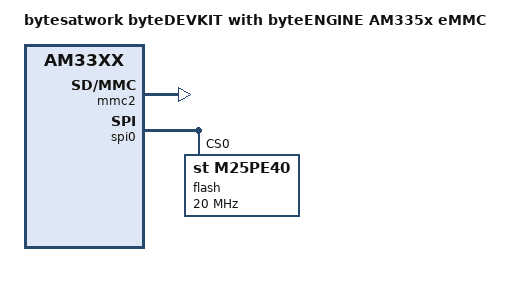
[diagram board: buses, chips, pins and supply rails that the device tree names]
// SPDX-License-Identifier: GPL-2.0
/*
 * Copyright (C) 2018 bytes at work AG
 *
 * Based on am335x-evm.dts
 *
 * Copyright (C) 2012 Texas Instruments Incorporated - http://www.ti.com/
 */

/dts-v1/;

#include "am335x-byteengine.dtsi"
#include "am335x-bytedevkit.dtsi"

/ {
	model = "bytesatwork byteDEVKIT with byteENGINE AM335x eMMC";
	compatible = "bytesatwork,byteengine-am335x", "ti,am33xx";
};

&mmc2 {
	status = "okay";
};

&spi0 {
	status = "okay";

	flash@0 {
		#address-cells = <1>;
		#size-cells = <1>;
		compatible = "st,m25pe40", "jedec,spi-nor";
		spi-max-frequency = <20000000>;
		reg = <0>;
	};
};
